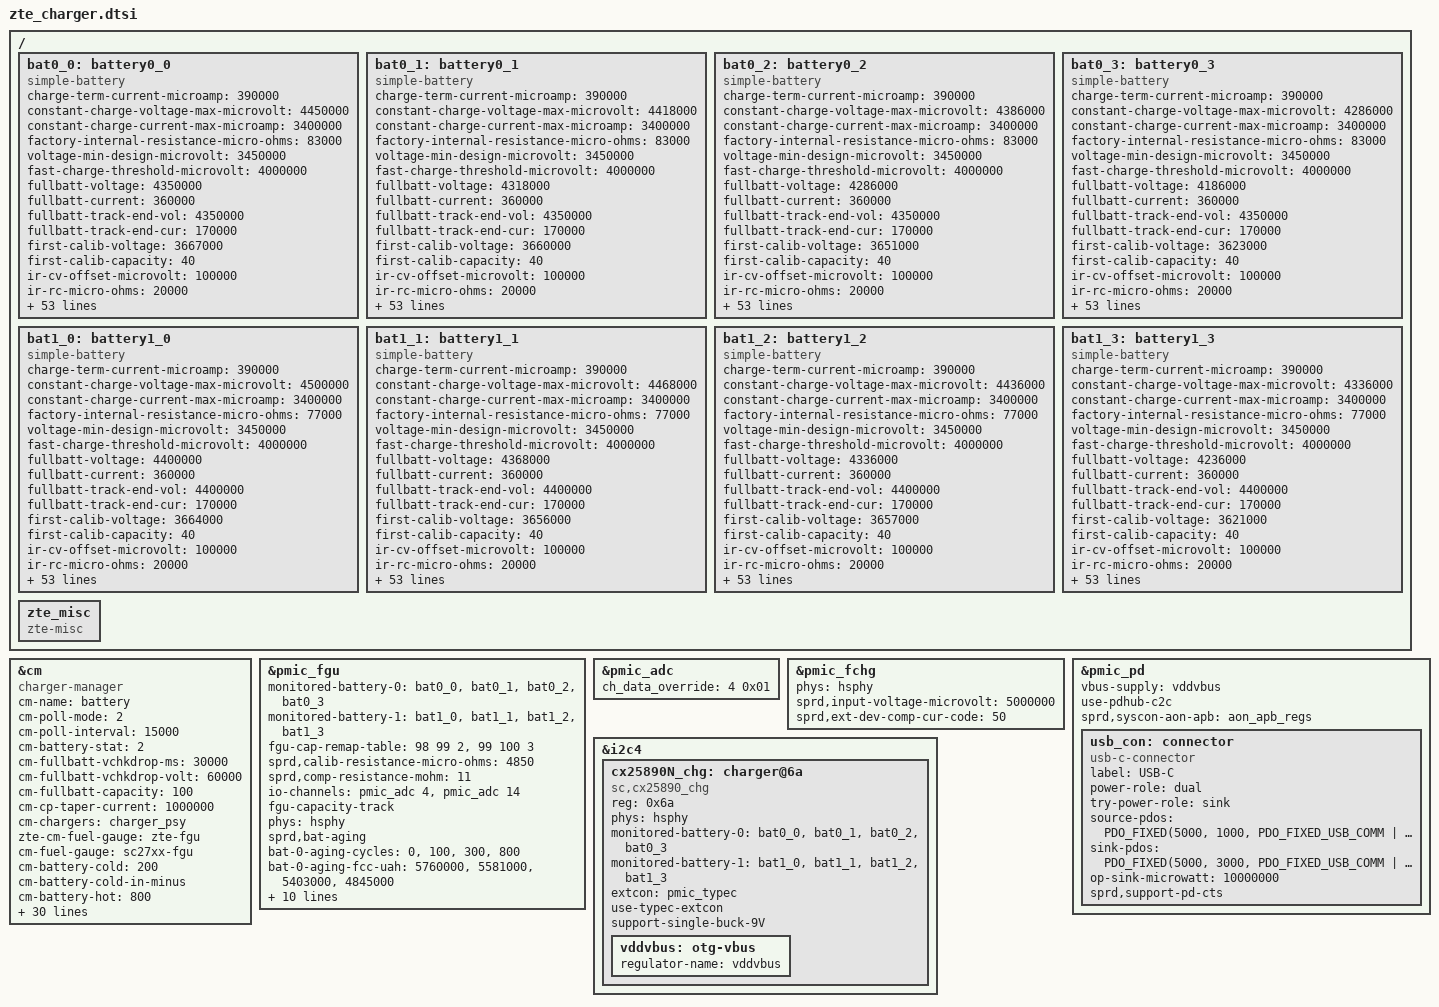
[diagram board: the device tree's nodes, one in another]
#include <dt-bindings/usb/pd.h>

/ {
	/*
	 *  bat:fenghua
	 *  bat1:haopeng
	 */
	bat0_0: battery0_0 {
		compatible = "simple-battery";
		status = "disabled";
	};

	bat0_1: battery0_1 {
		compatible = "simple-battery";
		status = "disabled";
	};

	bat0_2: battery0_2 {
		compatible = "simple-battery";
		status = "disabled";
	};

	bat0_3: battery0_3 {
		compatible = "simple-battery";
		status = "disabled";
	};

	bat1_0: battery1_0 {
		compatible = "simple-battery";
		status = "disabled";
	};

	bat1_1: battery1_1 {
		compatible = "simple-battery";
		status = "disabled";
	};

	bat1_2: battery1_2 {
		compatible = "simple-battery";
		status = "disabled";
	};

	bat1_3: battery1_3 {
		compatible = "simple-battery";
		status = "disabled";
	};
};

&bat0_0 {
	compatible = "simple-battery";
	status = "okay";

	charge-term-current-microamp = <390000>;
	constant-charge-voltage-max-microvolt = <4450000>;
	constant-charge-current-max-microamp = <3400000>;
	factory-internal-resistance-micro-ohms = <83000>;
	voltage-min-design-microvolt = <3450000>;
	fast-charge-threshold-microvolt = <4000000>;
	fullbatt-voltage = <4350000>;
	fullbatt-current = <360000>;
	fullbatt-track-end-vol = <4350000>;
	fullbatt-track-end-cur = <170000>;
	first-calib-voltage = <3667000>;
	first-calib-capacity = <40>;

	ir-cv-offset-microvolt = <100000>;
	ir-rc-micro-ohms = <20000>;
	ir-us-upper-limit-microvolt = <4500000>;

	charge-full-design-microamp-hours = <6000000>;
	/*charge-full-microamp-hours use 6000000 * 0.96 = 5760000*/
	charge-full-microamp-hours = <5760000>;

	ocv-capacity-celsius = <25>;
	ocv-capacity-table-0 = <4433000 100>, <4381000 95>, <4329000 90>,
				<4271000 85>, <4210000 80>, <4151000 75>,
				<4095000 70>, <4044000 65>, <3997000 60>,
				<3941000 55>, <3888000 50>, <3858000 45>,
				<3830000 40>, <3812000 35>, <3797000 30>,
				<3776000 25>, <3754000 20>, <3729000 15>,
				<3697000 10>, <3689000 5>, <3400000 0>;
	voltage-temp-table = <2351000 800>, <2253000 850>, <2143000 900>,
				<2022000 950>, <1894000 1000>, <1760000 1050>,
				<1622000 1100>, <1483000 1150>, <1347000 1200>,
				<1216000 1250>, <1091000 1300>, <975000 1350>,
				<865000 1400>, <768000 1450>, <676000 1500>,
				<598000 1550>, <525000 1600>, <464000 1650>;
	capacity-temp-table = <45 100>, <25 100>, <10 100>, <0 100>, <(-10) 99>;
	resistance-temp-table = <45 76>, <25 100>, <10 154>, <0 236>, <(-10) 558>;
	charge-sdp-current-microamp = <500000 500000>;
	charge-dcp-current-microamp = <3600000 2000000>;
	charge-cdp-current-microamp = <3600000 1500000>;
	charge-unknown-current-microamp = <1000000 1000000>;
	charge-fchg-current-microamp = <3600000 2000000>;

	dcp-jeita-temp-table = <1000 1020 0 4450000>,
				<1100 1120 980000 4450000>,
				<1150 1180 980000 4450000>,
				<1450 1420 3600000 4450000>,
				<1550 1520 2450000 4100000>;
	sdp-jeita-temp-table = <1000 1020 0 4450000>,
				<1100 1120 980000 4450000>,
				<1150 1180 980000 4450000>,
				<1450 1420 3600000 4450000>,
				<1550 1520 2450000 4100000>;
	cdp-jeita-temp-table = <1000 1020 0 4450000>,
				<1100 1120 980000 4450000>,
				<1150 1180 980000 4450000>,
				<1450 1420 3600000 4450000>,
				<1550 1520 2450000 4100000>;
	unknown-jeita-temp-table = <1000 1020 0 4450000>,
				<1100 1120 980000 4450000>,
				<1150 1180 980000 4450000>,
				<1450 1420 3600000 4450000>,
				<1550 1520 2450000 4100000>;
	fchg-jeita-temp-table = <1000 1020 0 4450000>,
				<1100 1120 980000 4450000>,
				<1150 1180 980000 4450000>,
				<1450 1420 3600000 4450000>,
				<1550 1520 2450000 4100000>;
};

&bat0_1 {
	compatible = "simple-battery";
	status = "okay";

	charge-term-current-microamp = <390000>;
	constant-charge-voltage-max-microvolt = <4418000>;
	constant-charge-current-max-microamp = <3400000>;
	factory-internal-resistance-micro-ohms = <83000>;
	voltage-min-design-microvolt = <3450000>;
	fast-charge-threshold-microvolt = <4000000>;
	fullbatt-voltage = <4318000>;
	fullbatt-current = <360000>;
	fullbatt-track-end-vol = <4350000>;
	fullbatt-track-end-cur = <170000>;
	first-calib-voltage = <3660000>;
	first-calib-capacity = <40>;

	ir-cv-offset-microvolt = <100000>;
	ir-rc-micro-ohms = <20000>;
	ir-us-upper-limit-microvolt = <4500000>;

	charge-full-design-microamp-hours = <6000000>;
	/*charge-full-microamp-hours use 6000000 * 0.96 = 5760000*/
	charge-full-microamp-hours = <5581000>;

	ocv-capacity-celsius = <25>;
	ocv-capacity-table-0 = <4401000 100>, <4351000 95>, <4300000 90>,
				<4244000 85>, <4185000 80>, <4128000 75>,
				<4073000 70>, <4024000 65>, <3979000 60>,
				<3924000 55>, <3873000 50>, <3844000 45>,
				<3817000 40>, <3799000 35>, <3785000 30>,
				<3764000 25>, <3743000 20>, <3719000 15>,
				<3688000 10>, <3680000 5>, <3400000 0>;
	voltage-temp-table = <2351000 800>, <2253000 850>, <2143000 900>,
				<2022000 950>, <1894000 1000>, <1760000 1050>,
				<1622000 1100>, <1483000 1150>, <1347000 1200>,
				<1216000 1250>, <1091000 1300>, <975000 1350>,
				<865000 1400>, <768000 1450>, <676000 1500>,
				<598000 1550>, <525000 1600>, <464000 1650>;
	capacity-temp-table = <45 100>, <25 100>, <10 100>, <0 100>, <(-10) 99>;
	resistance-temp-table = <45 76>, <25 100>, <10 154>, <0 236>, <(-10) 558>;
	charge-sdp-current-microamp = <500000 500000>;
	charge-dcp-current-microamp = <3600000 2000000>;
	charge-cdp-current-microamp = <3600000 1500000>;
	charge-unknown-current-microamp = <1000000 1000000>;
	charge-fchg-current-microamp = <3600000 2000000>;

	dcp-jeita-temp-table = <1000 1020 0 4418000>,
				<1100 1120 980000 4418000>,
				<1150 1180 980000 4418000>,
				<1450 1420 3600000 4418000>,
				<1550 1520 2450000 4100000>;
	sdp-jeita-temp-table = <1000 1020 0 4418000>,
				<1100 1120 980000 4418000>,
				<1150 1180 980000 4418000>,
				<1450 1420 3600000 4418000>,
				<1550 1520 2450000 4100000>;
	cdp-jeita-temp-table = <1000 1020 0 4418000>,
				<1100 1120 980000 4418000>,
				<1150 1180 980000 4418000>,
				<1450 1420 3600000 4418000>,
				<1550 1520 2450000 4100000>;
	unknown-jeita-temp-table = <1000 1020 0 4418000>,
				<1100 1120 980000 4418000>,
				<1150 1180 980000 4418000>,
				<1450 1420 3600000 4418000>,
				<1550 1520 2450000 4100000>;
	fchg-jeita-temp-table = <1000 1020 0 4418000>,
				<1100 1120 980000 4418000>,
				<1150 1180 980000 4418000>,
				<1450 1420 3600000 4418000>,
				<1550 1520 2450000 4100000>;
};

&bat0_2 {
	compatible = "simple-battery";
	status = "okay";

	charge-term-current-microamp = <390000>;
	constant-charge-voltage-max-microvolt = <4386000>;
	constant-charge-current-max-microamp = <3400000>;
	factory-internal-resistance-micro-ohms = <83000>;
	voltage-min-design-microvolt = <3450000>;
	fast-charge-threshold-microvolt = <4000000>;
	fullbatt-voltage = <4286000>;
	fullbatt-current = <360000>;
	fullbatt-track-end-vol = <4350000>;
	fullbatt-track-end-cur = <170000>;
	first-calib-voltage = <3651000>;
	first-calib-capacity = <40>;

	ir-cv-offset-microvolt = <100000>;
	ir-rc-micro-ohms = <20000>;
	ir-us-upper-limit-microvolt = <4500000>;

	charge-full-design-microamp-hours = <6000000>;
	/*charge-full-microamp-hours use 6000000 * 0.96 = 5760000*/
	charge-full-microamp-hours = <5403000>;

	ocv-capacity-celsius = <25>;
	ocv-capacity-table-0 = <4369000 100>, <4320000 95>, <4271000 90>,
				<4217000 85>, <4160000 80>, <4104000 75>,
				<4052000 70>, <4004000 65>, <3960000 60>,
				<3907000 55>, <3858000 50>, <3830000 45>,
				<3803000 40>, <3786000 35>, <3772000 30>,
				<3753000 25>, <3732000 20>, <3709000 15>,
				<3679000 10>, <3671000 5>, <3400000 0>;
	voltage-temp-table = <2351000 800>, <2253000 850>, <2143000 900>,
				<2022000 950>, <1894000 1000>, <1760000 1050>,
				<1622000 1100>, <1483000 1150>, <1347000 1200>,
				<1216000 1250>, <1091000 1300>, <975000 1350>,
				<865000 1400>, <768000 1450>, <676000 1500>,
				<598000 1550>, <525000 1600>, <464000 1650>;
	capacity-temp-table = <45 100>, <25 100>, <10 100>, <0 100>, <(-10) 99>;
	resistance-temp-table = <45 76>, <25 100>, <10 154>, <0 236>, <(-10) 558>;
	charge-sdp-current-microamp = <500000 500000>;
	charge-dcp-current-microamp = <3600000 2000000>;
	charge-cdp-current-microamp = <3600000 1500000>;
	charge-unknown-current-microamp = <1000000 1000000>;
	charge-fchg-current-microamp = <3600000 2000000>;

	dcp-jeita-temp-table = <1000 1020 0 4386000>,
				<1100 1120 980000 4386000>,
				<1150 1180 980000 4386000>,
				<1450 1420 3600000 4386000>,
				<1550 1520 2450000 4100000>;
	sdp-jeita-temp-table = <1000 1020 0 4386000>,
				<1100 1120 980000 4386000>,
				<1150 1180 980000 4386000>,
				<1450 1420 3600000 4386000>,
				<1550 1520 2450000 4100000>;
	cdp-jeita-temp-table = <1000 1020 0 4386000>,
				<1100 1120 980000 4386000>,
				<1150 1180 980000 4386000>,
				<1450 1420 3600000 4386000>,
				<1550 1520 2450000 4100000>;
	unknown-jeita-temp-table = <1000 1020 0 4386000>,
				<1100 1120 980000 4386000>,
				<1150 1180 980000 4386000>,
				<1450 1420 3600000 4386000>,
				<1550 1520 2450000 4100000>;
	fchg-jeita-temp-table = <1000 1020 0 4386000>,
				<1100 1120 980000 4386000>,
				<1150 1180 980000 4386000>,
				<1450 1420 3600000 4386000>,
				<1550 1520 2450000 4100000>;
};

&bat0_3 {
	compatible = "simple-battery";
	status = "okay";

	charge-term-current-microamp = <390000>;
	constant-charge-voltage-max-microvolt = <4286000>;
	constant-charge-current-max-microamp = <3400000>;
	factory-internal-resistance-micro-ohms = <83000>;
	voltage-min-design-microvolt = <3450000>;
	fast-charge-threshold-microvolt = <4000000>;
	fullbatt-voltage = <4186000>;
	fullbatt-current = <360000>;
	fullbatt-track-end-vol = <4350000>;
	fullbatt-track-end-cur = <170000>;
	first-calib-voltage = <3623000>;
	first-calib-capacity = <40>;

	ir-cv-offset-microvolt = <100000>;
	ir-rc-micro-ohms = <20000>;
	ir-us-upper-limit-microvolt = <4500000>;

	charge-full-design-microamp-hours = <6000000>;
	/*charge-full-microamp-hours use 6000000 * 0.96 = 5760000*/
	charge-full-microamp-hours = <4845000>;

	ocv-capacity-celsius = <25>;
	ocv-capacity-table-0 = <4269000 100>, <4225000 95>, <4182000 90>,
				<4133000 85>, <4081000 80>, <4032000 75>,
				<3985000 70>, <3942000 65>, <3902000 60>,
				<3855000 55>, <3811000 50>, <3785000 45>,
				<3762000 40>, <3747000 35>, <3734000 30>,
				<3716000 25>, <3698000 20>, <3677000 15>,
				<3650000 10>, <3643000 5>, <3400000 0>;
	voltage-temp-table = <2351000 800>, <2253000 850>, <2143000 900>,
				<2022000 950>, <1894000 1000>, <1760000 1050>,
				<1622000 1100>, <1483000 1150>, <1347000 1200>,
				<1216000 1250>, <1091000 1300>, <975000 1350>,
				<865000 1400>, <768000 1450>, <676000 1500>,
				<598000 1550>, <525000 1600>, <464000 1650>;
	capacity-temp-table = <45 100>, <25 100>, <10 100>, <0 100>, <(-10) 99>;
	resistance-temp-table = <45 76>, <25 100>, <10 154>, <0 236>, <(-10) 558>;
	charge-sdp-current-microamp = <500000 500000>;
	charge-dcp-current-microamp = <3600000 2000000>;
	charge-cdp-current-microamp = <3600000 1500000>;
	charge-unknown-current-microamp = <1000000 1000000>;
	charge-fchg-current-microamp = <3600000 2000000>;

	dcp-jeita-temp-table = <1000 1020 0 4286000>,
				<1100 1120 980000 4286000>,
				<1150 1180 980000 4286000>,
				<1450 1420 3600000 4286000>,
				<1550 1520 2450000 4100000>;
	sdp-jeita-temp-table = <1000 1020 0 4286000>,
				<1100 1120 980000 4286000>,
				<1150 1180 980000 4286000>,
				<1450 1420 3600000 4286000>,
				<1550 1520 2450000 4100000>;
	cdp-jeita-temp-table = <1000 1020 0 4286000>,
				<1100 1120 980000 4286000>,
				<1150 1180 980000 4286000>,
				<1450 1420 3600000 4286000>,
				<1550 1520 2450000 4100000>;
	unknown-jeita-temp-table = <1000 1020 0 4286000>,
				<1100 1120 980000 4286000>,
				<1150 1180 980000 4286000>,
				<1450 1420 3600000 4286000>,
				<1550 1520 2450000 4100000>;
	fchg-jeita-temp-table = <1000 1020 0 4286000>,
				<1100 1120 980000 4286000>,
				<1150 1180 980000 4286000>,
				<1450 1420 3600000 4286000>,
				<1550 1520 2450000 4100000>;
};

&bat1_0 {
	compatible = "simple-battery";
	status = "okay";

	charge-term-current-microamp = <390000>;
	constant-charge-voltage-max-microvolt = <4500000>;
	constant-charge-current-max-microamp = <3400000>;
	factory-internal-resistance-micro-ohms = <77000>;
	voltage-min-design-microvolt = <3450000>;
	fast-charge-threshold-microvolt = <4000000>;
	fullbatt-voltage = <4400000>;
	fullbatt-current = <360000>;
	fullbatt-track-end-vol = <4400000>;
	fullbatt-track-end-cur = <170000>;
	first-calib-voltage = <3664000>;
	first-calib-capacity = <40>;

	ir-cv-offset-microvolt = <100000>;
	ir-rc-micro-ohms = <20000>;
	ir-us-upper-limit-microvolt = <4500000>;

	charge-full-design-microamp-hours = <6000000>;
	/*charge-full-microamp-hours use 6000000 * 0.96 = 5760000*/
	charge-full-microamp-hours = <5760000>;

	ocv-capacity-celsius = <25>;
	ocv-capacity-table-0 = <4489000 100>, <4423000 95>, <4385000 90>,
				<4334000 85>, <4275000 80>, <4212000 75>,
				<4150000 70>, <4091000 65>, <4037000 60>,
				<3965000 55>, <3909000 50>, <3874000 45>,
				<3846000 40>, <3822000 35>, <3802000 30>,
				<3780000 25>, <3755000 20>, <3731000 15>,
				<3696000 10>, <3684000 5>, <3400000 0>;
	voltage-temp-table = <2351000 800>, <2253000 850>, <2143000 900>,
				<2022000 950>, <1894000 1000>, <1760000 1050>,
				<1622000 1100>, <1483000 1150>, <1347000 1200>,
				<1216000 1250>, <1091000 1300>, <975000 1350>,
				<865000 1400>, <768000 1450>, <676000 1500>,
				<598000 1550>, <525000 1600>, <464000 1650>;
	capacity-temp-table = <45 100>, <25 100>, <10 100>, <0 100>, <(-10) 99>;
	resistance-temp-table = <45 80>, <25 100>, <10 146>, <0 208>, <(-10) 428>;

	charge-sdp-current-microamp = <500000 500000>;
	charge-dcp-current-microamp = <4100000 2000000>;
	charge-cdp-current-microamp = <4100000 1500000>;
	charge-unknown-current-microamp = <1000000 1000000>;
	charge-fchg-current-microamp = <4100000 2000000>;

	dcp-jeita-temp-table = <1000 1020 0 4500000>,
				<1100 1120 1100000 4500000>,
				<1150 1180 1100000 4500000>,
				<1450 1420 4100000 4500000>,
				<1550 1520 2450000 4150000>;
	sdp-jeita-temp-table = <1000 1020 0 4500000>,
				<1100 1120 1100000 4500000>,
				<1150 1180 1100000 4500000>,
				<1450 1420 4100000 4500000>,
				<1550 1520 2450000 4150000>;
	cdp-jeita-temp-table = <1000 1020 0 4500000>,
				<1100 1120 1100000 4500000>,
				<1150 1180 1100000 4500000>,
				<1450 1420 4100000 4500000>,
				<1550 1520 2450000 4150000>;
	unknown-jeita-temp-table = <1000 1020 0 4500000>,
				<1100 1120 1100000 4500000>,
				<1150 1180 1100000 4500000>,
				<1450 1420 4100000 4500000>,
				<1550 1520 2450000 4150000>;
	fchg-jeita-temp-table = <1000 1020 0 4500000>,
				<1100 1120 1100000 4500000>,
				<1150 1180 1100000 4500000>,
				<1450 1420 4100000 4500000>,
				<1550 1520 2450000 4150000>;
};

&bat1_1 {
	compatible = "simple-battery";
	status = "okay";

	charge-term-current-microamp = <390000>;
	constant-charge-voltage-max-microvolt = <4468000>;
	constant-charge-current-max-microamp = <3400000>;
	factory-internal-resistance-micro-ohms = <77000>;
	voltage-min-design-microvolt = <3450000>;
	fast-charge-threshold-microvolt = <4000000>;
	fullbatt-voltage = <4368000>;
	fullbatt-current = <360000>;
	fullbatt-track-end-vol = <4400000>;
	fullbatt-track-end-cur = <170000>;
	first-calib-voltage = <3656000>;
	first-calib-capacity = <40>;

	ir-cv-offset-microvolt = <100000>;
	ir-rc-micro-ohms = <20000>;
	ir-us-upper-limit-microvolt = <4500000>;

	charge-full-design-microamp-hours = <6000000>;
	/*charge-full-microamp-hours use 6000000 * 0.96 = 5760000*/
	charge-full-microamp-hours = <5590000>;

	ocv-capacity-celsius = <25>;
	ocv-capacity-table-0 = <4457000 100>, <4393000 95>, <4356000 90>,
				<4307000 85>, <4249000 80>, <4188000 75>,
				<4128000 70>, <4071000 65>, <4018000 60>,
				<3948000 55>, <3894000 50>, <3860000 45>,
				<3833000 40>, <3810000 35>, <3790000 30>,
				<3769000 25>, <3745000 20>, <3721000 15>,
				<3687000 10>, <3676000 5>, <3400000 0>;
	voltage-temp-table = <2351000 800>, <2253000 850>, <2143000 900>,
				<2022000 950>, <1894000 1000>, <1760000 1050>,
				<1622000 1100>, <1483000 1150>, <1347000 1200>,
				<1216000 1250>, <1091000 1300>, <975000 1350>,
				<865000 1400>, <768000 1450>, <676000 1500>,
				<598000 1550>, <525000 1600>, <464000 1650>;
	capacity-temp-table = <45 100>, <25 100>, <10 100>, <0 100>, <(-10) 99>;
	resistance-temp-table = <45 80>, <25 100>, <10 146>, <0 208>, <(-10) 428>;

	charge-sdp-current-microamp = <500000 500000>;
	charge-dcp-current-microamp = <4100000 2000000>;
	charge-cdp-current-microamp = <4100000 1500000>;
	charge-unknown-current-microamp = <1000000 1000000>;
	charge-fchg-current-microamp = <4100000 2000000>;

	dcp-jeita-temp-table = <1000 1020 0 4468000>,
				<1100 1120 1100000 4468000>,
				<1150 1180 1100000 4468000>,
				<1450 1420 4100000 4468000>,
				<1550 1520 2450000 4150000>;
	sdp-jeita-temp-table = <1000 1020 0 4468000>,
				<1100 1120 1100000 4468000>,
				<1150 1180 1100000 4468000>,
				<1450 1420 4100000 4468000>,
				<1550 1520 2450000 4150000>;
	cdp-jeita-temp-table = <1000 1020 0 4468000>,
				<1100 1120 1100000 4468000>,
				<1150 1180 1100000 4468000>,
				<1450 1420 4100000 4468000>,
				<1550 1520 2450000 4150000>;
	unknown-jeita-temp-table = <1000 1020 0 4468000>,
				<1100 1120 1100000 4468000>,
				<1150 1180 1100000 4468000>,
				<1450 1420 4100000 4468000>,
				<1550 1520 2450000 4150000>;
	fchg-jeita-temp-table = <1000 1020 0 4468000>,
				<1100 1120 1100000 4468000>,
				<1150 1180 1100000 4468000>,
				<1450 1420 4100000 4468000>,
				<1550 1520 2450000 4150000>;
};

&bat1_2 {
	compatible = "simple-battery";
	status = "okay";

	charge-term-current-microamp = <390000>;
	constant-charge-voltage-max-microvolt = <4436000>;
	constant-charge-current-max-microamp = <3400000>;
	factory-internal-resistance-micro-ohms = <77000>;
	voltage-min-design-microvolt = <3450000>;
	fast-charge-threshold-microvolt = <4000000>;
	fullbatt-voltage = <4336000>;
	fullbatt-current = <360000>;
	fullbatt-track-end-vol = <4400000>;
	fullbatt-track-end-cur = <170000>;
	first-calib-voltage = <3657000>;
	first-calib-capacity = <40>;

	ir-cv-offset-microvolt = <100000>;
	ir-rc-micro-ohms = <20000>;
	ir-us-upper-limit-microvolt = <4500000>;

	charge-full-design-microamp-hours = <6000000>;
	/*charge-full-microamp-hours use 6000000 * 0.96 = 5760000*/
	charge-full-microamp-hours = <5421000>;

	ocv-capacity-celsius = <25>;
	ocv-capacity-table-0 = <4425000 100>, <4363000 95>, <4327000 90>,
				<4279000 85>, <4224000 80>, <4164000 75>,
				<4106000 70>, <4050000 65>, <4000000 60>,
				<3932000 55>, <3879000 50>, <3846000 45>,
				<3820000 40>, <3797000 35>, <3778000 30>,
				<3758000 25>, <3734000 20>, <3712000 15>,
				<3679000 10>, <3667000 5>, <3400000 0>;
	voltage-temp-table = <2351000 800>, <2253000 850>, <2143000 900>,
				<2022000 950>, <1894000 1000>, <1760000 1050>,
				<1622000 1100>, <1483000 1150>, <1347000 1200>,
				<1216000 1250>, <1091000 1300>, <975000 1350>,
				<865000 1400>, <768000 1450>, <676000 1500>,
				<598000 1550>, <525000 1600>, <464000 1650>;
	capacity-temp-table = <45 100>, <25 100>, <10 100>, <0 100>, <(-10) 99>;
	resistance-temp-table = <45 80>, <25 100>, <10 146>, <0 208>, <(-10) 428>;

	charge-sdp-current-microamp = <500000 500000>;
	charge-dcp-current-microamp = <4100000 2000000>;
	charge-cdp-current-microamp = <4100000 1500000>;
	charge-unknown-current-microamp = <1000000 1000000>;
	charge-fchg-current-microamp = <4100000 2000000>;

	dcp-jeita-temp-table = <1000 1020 0 4436000>,
				<1100 1120 1100000 4436000>,
				<1150 1180 1100000 4436000>,
				<1450 1420 4100000 4436000>,
				<1550 1520 2450000 4150000>;
	sdp-jeita-temp-table = <1000 1020 0 4436000>,
				<1100 1120 1100000 4436000>,
				<1150 1180 1100000 4436000>,
				<1450 1420 4100000 4436000>,
				<1550 1520 2450000 4150000>;
	cdp-jeita-temp-table = <1000 1020 0 4436000>,
				<1100 1120 1100000 4436000>,
				<1150 1180 1100000 4436000>,
				<1450 1420 4100000 4436000>,
				<1550 1520 2450000 4150000>;
	unknown-jeita-temp-table = <1000 1020 0 4436000>,
				<1100 1120 1100000 4436000>,
				<1150 1180 1100000 4436000>,
				<1450 1420 4100000 4436000>,
				<1550 1520 2450000 4150000>;
	fchg-jeita-temp-table = <1000 1020 0 4436000>,
				<1100 1120 1100000 4436000>,
				<1150 1180 1100000 4436000>,
				<1450 1420 4100000 4436000>,
				<1550 1520 2450000 4150000>;
};

&bat1_3 {
	compatible = "simple-battery";
	status = "okay";

	charge-term-current-microamp = <390000>;
	constant-charge-voltage-max-microvolt = <4336000>;
	constant-charge-current-max-microamp = <3400000>;
	factory-internal-resistance-micro-ohms = <77000>;
	voltage-min-design-microvolt = <3450000>;
	fast-charge-threshold-microvolt = <4000000>;
	fullbatt-voltage = <4236000>;
	fullbatt-current = <360000>;
	fullbatt-track-end-vol = <4400000>;
	fullbatt-track-end-cur = <170000>;
	first-calib-voltage = <3621000>;
	first-calib-capacity = <40>;

	ir-cv-offset-microvolt = <100000>;
	ir-rc-micro-ohms = <20000>;
	ir-us-upper-limit-microvolt = <4500000>;

	charge-full-design-microamp-hours = <6000000>;
	/*charge-full-microamp-hours use 6000000 * 0.96 = 5760000*/
	charge-full-microamp-hours = <4892000>;

	ocv-capacity-celsius = <25>;
	ocv-capacity-table-0 = <4325000 100>, <4269000 95>, <4237000 90>,
				<4193000 85>, <4143000 80>, <4090000 75>,
				<4037000 70>, <3987000 65>, <3941000 60>,
				<3880000 55>, <3832000 50>, <3803000 45>,
				<3779000 40>, <3758000 35>, <3741000 30>,
				<3723000 25>, <3702000 20>, <3681000 15>,
				<3651000 10>, <3641000 5>, <3400000 0>;
	voltage-temp-table = <2351000 800>, <2253000 850>, <2143000 900>,
				<2022000 950>, <1894000 1000>, <1760000 1050>,
				<1622000 1100>, <1483000 1150>, <1347000 1200>,
				<1216000 1250>, <1091000 1300>, <975000 1350>,
				<865000 1400>, <768000 1450>, <676000 1500>,
				<598000 1550>, <525000 1600>, <464000 1650>;
	capacity-temp-table = <45 100>, <25 100>, <10 100>, <0 100>, <(-10) 99>;
	resistance-temp-table = <45 80>, <25 100>, <10 146>, <0 208>, <(-10) 428>;

	charge-sdp-current-microamp = <500000 500000>;
	charge-dcp-current-microamp = <4100000 2000000>;
	charge-cdp-current-microamp = <4100000 1500000>;
	charge-unknown-current-microamp = <1000000 1000000>;
	charge-fchg-current-microamp = <4100000 2000000>;

	dcp-jeita-temp-table = <1000 1020 0 4336000>,
				<1100 1120 1100000 4336000>,
				<1150 1180 1100000 4336000>,
				<1450 1420 4100000 4336000>,
				<1550 1520 2450000 4150000>;
	sdp-jeita-temp-table = <1000 1020 0 4336000>,
				<1100 1120 1100000 4336000>,
				<1150 1180 1100000 4336000>,
				<1450 1420 4100000 4336000>,
				<1550 1520 2450000 4150000>;
	cdp-jeita-temp-table = <1000 1020 0 4336000>,
				<1100 1120 1100000 4336000>,
				<1150 1180 1100000 4336000>,
				<1450 1420 4100000 4336000>,
				<1550 1520 2450000 4150000>;
	unknown-jeita-temp-table = <1000 1020 0 4336000>,
				<1100 1120 1100000 4336000>,
				<1150 1180 1100000 4336000>,
				<1450 1420 4100000 4336000>,
				<1550 1520 2450000 4150000>;
	fchg-jeita-temp-table = <1000 1020 0 4336000>,
				<1100 1120 1100000 4336000>,
				<1150 1180 1100000 4336000>,
				<1450 1420 4100000 4336000>,
				<1550 1520 2450000 4150000>;
};

&cm {
	compatible = "charger-manager";
	status = "okay";
	cm-name = "battery";
	cm-poll-mode = <2>;
	cm-poll-interval = <15000>;
	cm-battery-stat = <2>;

	cm-fullbatt-vchkdrop-ms = <30000>;
	cm-fullbatt-vchkdrop-volt = <60000>;
	cm-fullbatt-capacity = <100>;
	/*Charge pump target charge current*/
	cm-cp-taper-current = <1000000>;

	cm-chargers = "charger_psy";
	zte-cm-fuel-gauge = "zte-fgu";
	cm-fuel-gauge = "sc27xx-fgu";

	/* in deci centigrade */
	cm-battery-cold = <200>;
	cm-battery-cold-in-minus;
	cm-battery-hot = <800>;
	cm-battery-temp-diff = <100>;

	/* Allow charging for 6hr */
	cm-charging-max = <21600000>;
	/* recovery charging after stop charging 45min */
	cm-discharging-max = <2700000>;

	/* the interval to feed charger watchdog */
	cm-wdt-interval = <60>;

	/* drop voltage in microVolts to allow shutdown */
	cm-shutdown-voltage = <3100000>;

	/* when 99% of the time is exceeded, it will be forced to 100% */
	cm-tickle-time-out = <1500>;

	/* how much time to allow capacity change */
	cm-one-cap-time = <30>;

	/* because kernel not load thermal-gerneric-adc.ko in charger mode, then battery uevent can't broadcast to ztecharger */
	/* cm-thermal-zone = "board-thmzone"; */

	/* when the safe charging voltage is exceeded, stop charging */
	cm-charge-voltage-max = <6500000>;
	cm-fast-charge-voltage-max = <10500000>;
	cm-flash-charge-voltage-max = <12000000>;
	cm-wireless-charge-voltage-max = <6500000>;
	cm-wireless-fast-charge-voltage-max = <12000000>;
	/* drop voltage in microVolts to restart charging */
	cm-charge-voltage-drop = <700000>;
	cm-fast-charge-voltage-drop = <700000>;
	cm-flash-charge-voltage-drop = <1000000>;
	cm-wireless-charge-voltage-drop = <700000>;
	cm-wireless-fast-charge-voltage-drop = <1000000>;

	/* sprd_fchg parameter */
	sprd,support-fchg;
	sprd,support-sfcp;
	sprd,pd-fixed-max-microwatt = <18000000>;

	monitored-battery-0 = <&bat0_0 &bat0_1 &bat0_2 &bat0_3>;
	monitored-battery-1 = <&bat1_0 &bat1_1 &bat1_2 &bat1_3>;
	cm-capacity-track;
	cm-keep-awake;

	phys = <&hsphy>;
	pd-extcon-enable;
	extcon = <&pmic_typec>, <&pmic_pd>;
	use-typec-extcon;
};

&pmic_fgu {
	monitored-battery-0 = <&bat0_0 &bat0_1 &bat0_2 &bat0_3>;
	monitored-battery-1 = <&bat1_0 &bat1_1 &bat1_2 &bat1_3>;
	fgu-cap-remap-table = <98 99 2>, <99 100 3>;
	sprd,calib-resistance-micro-ohms = <4850>;
	sprd,comp-resistance-mohm = <11>;

	io-channels = <&pmic_adc 4>, <&pmic_adc 14>;
	io-channel-names = "bat-temp", "charge-vol";

	fgu-capacity-track;
	phys = <&hsphy>;

	sprd,bat-aging;
	bat-0-aging-cycles = <0>, <100>, <300>, <800>;
	bat-0-aging-fcc-uah = <5760000>, <5581000>, <5403000>, <4845000>;
	bat-1-aging-cycles = <0>, <100>, <300>, <800>;
	bat-1-aging-fcc-uah = <5760000>, <5590000>, <5421000>, <4892000>;
	sprd,relax-counter-threshold = <580>;
	sprd,relax-current-threshold = <30>;
	sprd,capacity-sleep-calibration;

	sprd,capacity-boot-calibration;
	use-typec-extcon;
	extcon = <&pmic_typec>;
	sprd,zte-low-temp-algo;
};

&pmic_adc {
	ch_data_override = <4 0x01>;
};

&pmic_fchg {
	status = "okay";
 	phys = <&hsphy>;
	sprd,input-voltage-microvolt = <5000000>;
	sprd,ext-dev-comp-cur-code = <50>;
};

&pmic_pd {
	status = "okay";
	vbus-supply = <&vddvbus>;
	use-pdhub-c2c;
	sprd,syscon-aon-apb = <&aon_apb_regs>;
	usb_con: connector {
		compatible = "usb-c-connector";
		label = "USB-C";
		power-role = "dual";
		try-power-role = "sink";
		source-pdos = <PDO_FIXED(5000, 1000, PDO_FIXED_USB_COMM | PDO_FIXED_SUSPEND |
			                 PDO_FIXED_DUAL_ROLE | PDO_FIXED_DATA_SWAP)>;
		sink-pdos = <PDO_FIXED(5000, 3000, PDO_FIXED_USB_COMM | PDO_FIXED_DUAL_ROLE |
				       PDO_FIXED_DATA_SWAP)>;
		op-sink-microwatt = <10000000>;

		sprd,support-pd-cts;
	};
};

&i2c4 {
	status = "okay";

	cx25890N_chg: charger@6a {
		compatible = "sc,cx25890_chg";
		reg = <0x6a>;
		phys = <&hsphy>;
		monitored-battery-0 = <&bat0_0 &bat0_1 &bat0_2 &bat0_3>;
		monitored-battery-1 = <&bat1_0 &bat1_1 &bat1_2 &bat1_3>;
		extcon = <&pmic_typec>;
		use-typec-extcon;
		support-single-buck-9V;
		vddvbus:otg-vbus {
			regulator-name = "vddvbus";
		};
	};
};

/ {
	zte_misc: zte_misc {
		status = "okay";
		compatible = "zte-misc";
	};
};

#include "../bat_setting/battery_protect_policy_080509200196.dtsi"
